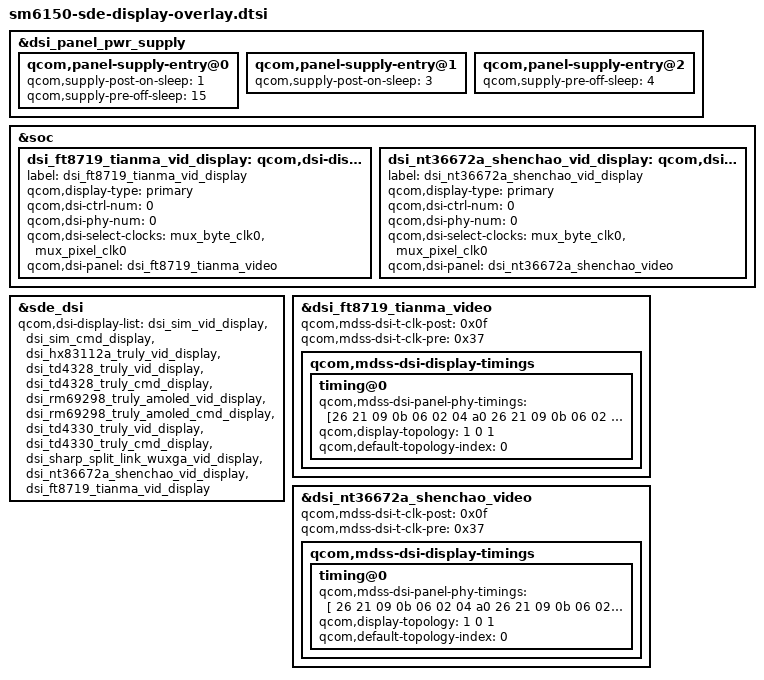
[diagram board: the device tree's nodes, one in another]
/* SPDX-License-Identifier: GPL-2.0 */

#include "dsi-panel-ft8719-tianma-fhd-video.dtsi"
#include "dsi-panel-nt36672a-shenchao-fhd-video.dtsi"

&dsi_panel_pwr_supply {
	qcom,panel-supply-entry@0 {
		qcom,supply-post-on-sleep = <1>;
		qcom,supply-pre-off-sleep = <15>;
	};

	qcom,panel-supply-entry@1 {
		qcom,supply-post-on-sleep = <3>;
	};

	qcom,panel-supply-entry@2 {
		/delete-property/ qcom,supply-post-on-sleep;
		qcom,supply-pre-off-sleep = <4>;
	};
};

&soc {
	dsi_ft8719_tianma_vid_display: qcom,dsi-display@10 {
		label = "dsi_ft8719_tianma_vid_display";
		qcom,display-type = "primary";

		qcom,dsi-ctrl-num = <0>;
		qcom,dsi-phy-num = <0>;
		qcom,dsi-select-clocks = "mux_byte_clk0", "mux_pixel_clk0";

		qcom,dsi-panel = <&dsi_ft8719_tianma_video>;
	};

    dsi_nt36672a_shenchao_vid_display: qcom,dsi-display@11 {
		label = "dsi_nt36672a_shenchao_vid_display";
		qcom,display-type = "primary";

		qcom,dsi-ctrl-num = <0>;
		qcom,dsi-phy-num = <0>;
		qcom,dsi-select-clocks = "mux_byte_clk0", "mux_pixel_clk0";

		qcom,dsi-panel = <&dsi_nt36672a_shenchao_video>;
	};
};

&sde_dsi {
	qcom,dsi-display-list =
			<&dsi_sim_vid_display
			&dsi_sim_cmd_display
			&dsi_hx83112a_truly_vid_display
			&dsi_td4328_truly_vid_display
			&dsi_td4328_truly_cmd_display
			&dsi_rm69298_truly_amoled_vid_display
			&dsi_rm69298_truly_amoled_cmd_display
			&dsi_td4330_truly_vid_display
			&dsi_td4330_truly_cmd_display
			&dsi_sharp_split_link_wuxga_vid_display
			&dsi_nt36672a_shenchao_vid_display
			&dsi_ft8719_tianma_vid_display>;
};

&dsi_ft8719_tianma_video {
	qcom,mdss-dsi-t-clk-post = <0x0f>;
	qcom,mdss-dsi-t-clk-pre = <0x37>;
	qcom,mdss-dsi-display-timings {
		timing@0{
			qcom,mdss-dsi-panel-phy-timings =
			[26 21 09 0b 06 02 04 a0
                         26 21 09 0b 06 02 04 a0
                         26 21 09 0b 06 02 04 a0
                         26 21 09 0b 06 02 04 a0
                         26 20 0a 0b 06 02 04 a0];
			qcom,display-topology = <1 0 1>;
			qcom,default-topology-index = <0>;
		};
	};
};

&dsi_nt36672a_shenchao_video {
    qcom,mdss-dsi-t-clk-post = <0x0f>;
	qcom,mdss-dsi-t-clk-pre = <0x37>;
	qcom,mdss-dsi-display-timings {
		timing@0{
			qcom,mdss-dsi-panel-phy-timings =
                               [
                               26 21 09 0b 06 02 04 a0
                               26 21 09 0b 06 02 04 a0
                               26 21 09 0b 06 02 04 a0
                               26 21 09 0b 06 02 04 a0
                               26 20 0a 0b 06 02 04 a0];

			qcom,display-topology = <1 0 1>;
			qcom,default-topology-index = <0>;
		};
	};
};
